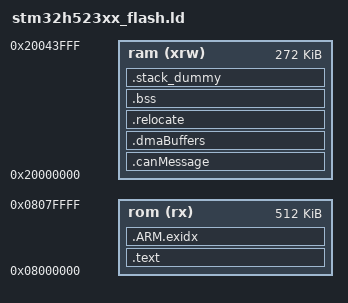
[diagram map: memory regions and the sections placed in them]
/*
 ******************************************************************************
 **
 ** @file        : LinkerScript.ld
 **
 ** @author      : Auto-generated by STM32CubeIDE
 **
 ** @brief       : Linker script for STM32H523xx Device from STM32H5 series
 **                      512Kbytes FLASH
 **                      272Kbytes RAM
 **
 **                Set heap size, stack size and stack location according
 **                to application requirements.
 **
 **                Set memory bank area and size if external memory is used
 **
 **  Target      : STMicroelectronics STM32
 **
 **  Distribution: The file is distributed as is, without any warranty
 **                of any kind.
 **
 ******************************************************************************
 ** @attention
 **
 ** Copyright (c) 2023 STMicroelectronics.
 ** All rights reserved.
 **
 ** This software is licensed under terms that can be found in the LICENSE file
 ** in the root directory of this software component.
 ** If no LICENSE file comes with this software, it is provided AS-IS.
 **
 ******************************************************************************
 */

/* Entry Point */
ENTRY(Reset_Handler)


/* Memories definition */
MEMORY
{
  ram    (xrw)   : ORIGIN = 0x20000000,   LENGTH = 272K
  rom    (rx)    : ORIGIN = 0x08000000,   LENGTH = 512K
}

/* Section Definitions */
SECTIONS
{
    .text :
    {
        . = ALIGN(4);
        _sfixed = .;
        KEEP(*(.vectors .vectors.*))
        *(.text .text.* .gnu.linkonce.t.*)
        *(.glue_7t) *(.glue_7)
        *(.rodata .rodata* .gnu.linkonce.r.*)
        *(.ARM.extab* .gnu.linkonce.armextab.*)

        /* Support C constructors, and C destructors in both user code
           and the C library. This also provides support for C++ code. */
        . = ALIGN(4);
        KEEP(*(.init))
        . = ALIGN(4);
        __preinit_array_start = .;
        KEEP (*(.preinit_array))
        __preinit_array_end = .;

        . = ALIGN(4);
        __init_array_start = .;
        KEEP (*(SORT(.init_array.*)))
        KEEP (*(.init_array))
        __init_array_end = .;

        . = ALIGN(4);
        KEEP (*crtbegin.o(.ctors))
        KEEP (*(EXCLUDE_FILE (*crtend.o) .ctors))
        KEEP (*(SORT(.ctors.*)))
        KEEP (*crtend.o(.ctors))

        . = ALIGN(4);
        KEEP(*(.fini))

        . = ALIGN(4);
        __fini_array_start = .;
        KEEP (*(.fini_array))
        KEEP (*(SORT(.fini_array.*)))
        __fini_array_end = .;

        KEEP (*crtbegin.o(.dtors))
        KEEP (*(EXCLUDE_FILE (*crtend.o) .dtors))
        KEEP (*(SORT(.dtors.*)))
        KEEP (*crtend.o(.dtors))

        . = ALIGN(4);
        _efixed = .;            /* End of text section */
    } > rom

    /* .ARM.exidx is sorted, so has to go in its own output section.  */
    PROVIDE_HIDDEN (__exidx_start = .);
    .ARM.exidx :
    {
      *(.ARM.exidx* .gnu.linkonce.armexidx.*)
    } > rom
    PROVIDE_HIDDEN (__exidx_end = .);

    . = ALIGN(4);
    _etext = .;

	/* CAN message buffers must be in the first 64K of RAM */
    .canMessage (NOLOAD) :
    {
        . = ALIGN(4);
        _sCanMessage = . ;
		*(.CanMessage .CanMessage.*)
        . = ALIGN(4);
        _eCanMessage = . ;
    } > ram

    /* DMA programming and write-back memory, here because they are volatile so we must't CRC them when we check for data corruption */
    .dmaBuffers (NOLOAD) :
    {
    	. = ALIGN(16);
    	_sDmaBuffers = . ;
    	*(.DmaBuffers .DmaBuffers.*)
    	. = ALIGN(4);
    	_eDmaBuffers = . ;
    } > ram

    .relocate : AT (_etext)
    {
        . = ALIGN(4);
        _srelocate = .;
        *(.ramfunc .ramfunc.*);
        *(.data .data.*);
        . = ALIGN(4);
        _erelocate = .;
    } > ram

 	_firmware_crc = _etext + (_erelocate - _srelocate);		/* We append the CRC32 to the binary file. This is its offset in memory. */

    /* .bss section which is used for uninitialized data */
    .bss (NOLOAD) :
    {
        . = ALIGN(4);
        _sbss = . ;
        _szero = .;
        *(.bss .bss.*)
        *(COMMON)
        . = ALIGN(4);
        _ebss = . ;
        _ezero = .;
    } > ram

    . = ALIGN(4);
    _end = . ;

	/* .stack_dummy section doesn't contains any symbols. It is only
       used for linker to calculate size of stack sections, and assign
       values to stack symbols later */
    .stack_dummy :
    {
        *(.stack*)
    } > ram

    /* Set stack top to end of ram, and stack limit move down by
     * size of stack_dummy section */
    __StackTop = ORIGIN(ram) + LENGTH(ram);
    __StackLimit = __StackTop - SIZEOF(.stack_dummy);
    PROVIDE(_sstack = __StackLimit);
    PROVIDE(_estack = __StackTop);
}
